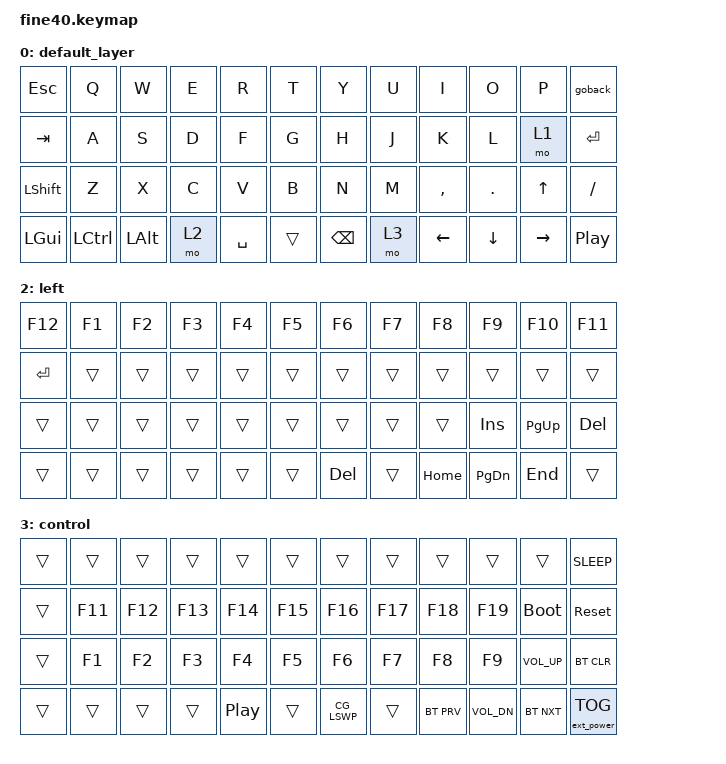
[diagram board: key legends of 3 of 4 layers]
/*
 * Aidan Smith (2021)
 *
 * SPDX-License-Identifier: MIT
 */

#include <behaviors.dtsi>
#include <dt-bindings/zmk/keys.h>
#include <dt-bindings/zmk/bt.h>
#include <dt-bindings/zmk/ext_power.h>

/ {
	keymap {
		compatible = "zmk,keymap";

		default_layer {
			bindings = <
				&kp ESC   &kp Q    &kp W    &kp E    &kp R    &kp T    &kp Y    &kp U    &kp I     &kp O    &kp P     &goback
				&kp TAB   &kp A    &kp S    &kp D    &kp F    &kp G    &kp H    &kp J    &kp K     &kp L    &mo 1     &kp RET
				&kp LSHFT &kp Z    &kp X    &kp C    &kp V    &kp B    &kp N    &kp M    &kp COMMA &kp DOT  &kp UP    &kp FSLH
				&kp LGUI  &kp LCTL &kp LALT &mo 2    &kp SPACE &trans  &kp BSPC &mo 3    &kp LEFT  &kp DOWN &kp RIGHT &kp C_PP
			>;

			sensor-bindings = <&inc_dec_kp C_VOL_DN C_VOL_UP>;
		};

		right {
			bindings = <
				&kp GRAVE  &kp N1     &kp N2 	 &kp N3     &kp N4     &kp N5     &kp N6     &kp N7     &kp N8    &kp N9     &kp N0  &kp BSLH
				&kp LSHFT  &kp AT     &kp DLLR   &kp MINUS  &kp EXCL   &kp LBKT   &kp RBKT   &kp SEMI   &kp APOS  &kp EQUAL  &trans  &trans
				&trans     &trans     &kp PRCNT  &kp POUND  &kp CARET  &kp LPAR   &kp RPAR   &kp AMPS   &kp ASTRK &kp PG_UP  &trans
				&trans     &trans     &trans     &trans     &mt LCTL SPACE &trans &mt LALT BSPC  &trans &kp HOME  &kp PG_DN  &kp END   &trans
			>;
		};

		left {
			bindings = <
				&kp F12 &kp F1 &kp F2 &kp F3 &kp F4 &kp F5 &kp F6  &kp F7 &kp F8 &kp F9 &kp F10 &kp F11	
				&kp RET &trans &trans &trans &trans &trans &trans  &trans &trans &trans &trans  &trans
				&trans  &trans &trans &trans &trans &trans &trans  &trans &trans &kp INS &kp PG_UP  &kp DEL  
				&trans  &trans &trans &trans &trans &trans &kp DEL &trans &kp HOME &kp PG_DN  &kp END  &trans
			>;
			
			sensor-bindings = <&inc_dec_kp C_BRI_DEC C_BRI_INC>;
		};

		control {
			bindings = <
				&trans &trans  &trans  &trans  &trans   &trans  &trans  &trans  &trans     &trans       &trans       &kp K_SLEEP
				&trans &kp F11 &kp F12 &kp F13 &kp F14  &kp F15 &kp F16 &kp F17 &kp F18    &kp F19      &bootloader  &sys_reset
				&trans &kp F1  &kp F2  &kp F3  &kp F4   &kp F5  &kp F6  &kp F7  &kp F8     &kp F9       &kp C_VOL_UP &bt BT_CLR
				&trans &trans  &trans  &trans  &kp C_PP &trans  &CG_LSWP  &trans  &bt BT_PRV &kp C_VOL_DN &bt BT_NXT   &ext_power EP_TOG
			>;
		};
	};
};

/ {
    macros {
        goback: goback {
            label = "goback";
            compatible = "zmk,behavior-macro";
            #binding-cells = <0>;
            bindings
                = <&macro_press &kp LCTRL>
		, <&macro_press &kp LSHFT>
                , <&macro_tap &kp LEFT>
                , <&macro_release &kp LSHFT>
		, <&macro_release &kp LCTRL>
		, <&macro_tap &kp DEL>
                ;
        };
    };
}; 
